# nrf9120_mlm1_modem register map
Vendor: Nordic Semiconductor; Series: nrf91; File version: 1
CPU: CM4 r0p1, little endian, MPU, no FPU, 3 interrupt priority bits
Registers are 32-bit, read-write, reset 0x0 unless marked. A register's access mark holds for its fields unless they carry their own. Offsets are from the block's base; [hi:lo] are bit positions; 'fields as' and 'values as' point back to an identical list.

## RCOSC32K — 32.768 kHz RC oscillator
Base 0x40012000
0x00 TASKS_CAL wo — Start calibration of LFRC or LFULP oscillator
  [0] TASKS_CAL
    1=Trigger task
0x04 TASKS_CTSTART wo — Start calibration timer
  [0] TASKS_CTSTART
    1=Trigger task
0x08 TASKS_CTSTOP wo — Stop calibration timer
  [0] TASKS_CTSTOP
    1=Trigger task
0x10C EVENTS_DONE — Calibration of LFCLK RC oscillator complete event
  [0] EVENTS_DONE
    0=NotGenerated (Event not generated); 1=Generated (Event generated)
0x300 INTEN — Enable or disable interrupt
  [3] DONE — Enable or disable interrupt for event DONE
    0=Disabled; 1=Enabled
0x304 INTENSET — Enable interrupt
  [3] DONE — Write '1' to enable interrupt for event DONE
    on read: 0=Disabled (Read: Disabled); 1=Enabled (Read: Enabled) | on write: 1=Set (Enable)
0x308 INTENCLR — Disable interrupt
  [3] DONE — Write '1' to disable interrupt for event DONE
    on read: 0=Disabled (Read: Disabled); 1=Enabled (Read: Enabled) | on write: 1=Clear (Disable)
0x30C INTPEND ro — Pending interrupts
  [3] DONE — Read pending status of interrupt for event DONE
    on read: 0=NotPending (Read: Not pending); 1=Pending (Read: Pending)
0x420 RCOSC32KIFINE ro — Fine calibration read value for 32.768 kHz RC oscillator (retained register, same reset behaviour as RESETREAS)
  [9:0] RCOSC32KIFINE — Fine calibration read value for 32.768 kHz RC oscillator
0x424 RCOSC32KICOARSE ro — Coarse calibration read value for 32.768 kHz RC oscillator (Retained register, same reset behaviour as RESETREAS)
  [5:0] RCOSC32KICOARSE — Coarse calibration read value for 32.768 kHz RC oscillator
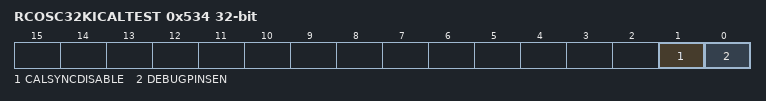
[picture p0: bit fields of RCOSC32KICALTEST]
0x534 RCOSC32KICALTEST — 32.768 kHz RC oscillator calibration debug register (retained register, same reset behaviour as RESETREAS)
  [1] CALSYNCDISABLE — Disable calSync auto-calibration
    1=Disabled (calSync auto-calibration disabled); 0=Enabled (calSync auto-calibration enabled)
  [0] DEBUGPINSEN — Enable debug pins: calSync on P0.8 (input); ck32Ki on P0.13 (output); rcosc32KiCalib on P0.19 (output)
    0=Disabled (Pins in normal operation); 1=Enabled (Pins mapped for debug)
0x538 CTIV — Calibration timer interval (retained register, same reset behaviour as RESETREAS)
  [6:0] CTIV — Calibration timer interval in multiple of 0.25 seconds. Range: 0.25 seconds to 31.75 seconds.
0x53C RCOSC32KICALLENGTH reset 0x2 — 32kHz RC oscillator calibration length (retained register, same reset behaviour as RESETREAS)
  [2:0] RCOSC32KICALLENGTH — 32kHz RC oscillator calibration length in number of cycles
    0=N64 (64 cycles); 1=N128 (128 cycles); 2=N256 (256 cycles); 3=N512 (512 cycles)
0x540 RCOSC32KICOARSEIN reset 0x1F — RCOSC coarse calibration input (retained register, same reset behaviour as RESETREAS)
  [5:0] RCOSC32KICOARSEIN — RCOSC coarse calibration input
0x54C RCOSC32KICIRC reset 0x1 — Rotating current source for for 32.768 kHz RC oscillator (retained register, same reset behaviour as RESETREAS)
  [0] RCS — Enable or disable use of external rotating current source for 32.768 kHz RC oscillator
    0=Disabled; 1=Enabled
0x584 ATECLOCK — Analog test bus control for clock modules
  [0] RCOSC32K — Connect or disconnect 32.768 kHz RC oscillator to analog test bus
    0=Disconnected; 1=Connected (Connect internal regulator output to ATB0)
0x5B0 LFULP32KICIRC — Rotating current source for 32.768 kHz ULP RC oscillator
  [0] RCS — Enable or disable use of external rotating current source for 32.768 kHz ULP RC oscillator
    0=Disabled; 1=Enabled
0x5B4 LFULP32KICALLENGTH — 32kHz LFULP RC oscillator calibration length
  [2:0] LFULP32KICALLENGTH — 32kHz ULP RC oscillator calibration length in number of cycles
    values as RCOSC32KICALLENGTH.RCOSC32KICALLENGTH
0x5B8 LFULP32KICOARSE — Coarse calibration read value for 32.768 kHz ULP RC oscillator
  [5:0] LFULP32KICOARSE
